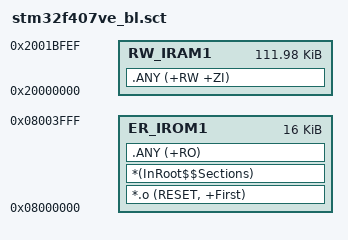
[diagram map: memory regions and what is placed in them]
; Bootloader scatter: first 16KB Flash (sector 0)
; SRAM 0x2001BFF0..0x2001BFFF is reserved for APP->BL magic.
; Do NOT include those 16 bytes in RW_IRAM1: Keil places the stack at the
; top of the region, and a 0x1C000 region would overwrite the magic on reset
; before main() can read it — BL would jump back to APP immediately.
LR_IROM1 0x08000000 0x00004000  {
  ER_IROM1 0x08000000 0x00004000  {
    *.o (RESET, +First)
    *(InRoot$$Sections)
    .ANY (+RO)
  }
  RW_IRAM1 0x20000000 0x0001BFF0  {
    .ANY (+RW +ZI)
  }
}
